# COMPUTE_CLUSTER0_GIC500SS_GICSS_VBUSM_GASKET_CFG_GICSS_VBUSM_GASKET_CFG register map
Vendor: Texas Instruments
Peripheral module from a debugger description file (folder J721S2).
Registers are 32-bit, read-only, reset 0x0 unless marked. A register's access mark holds for its fields unless they carry their own. Offsets are as the file gives them; lines under a group give offsets from that group; [hi:lo] are bit positions; {n}, {i} and the like mark numbered series; 'fields as' and 'values as' point back to an identical list; <NAME> marks a mode.

## COMPUTE_CLUSTER0_GIC500SS_GICSS_VBUSM_GASKET_CFG_GICSS_VBUSM_GASKET_CFG
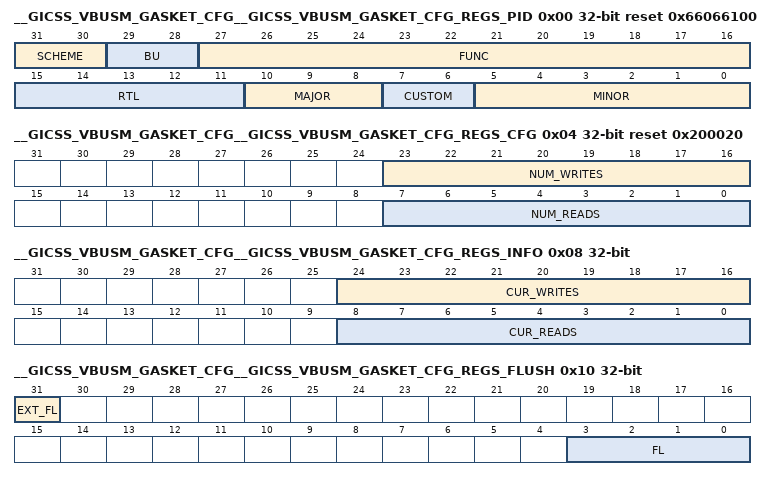
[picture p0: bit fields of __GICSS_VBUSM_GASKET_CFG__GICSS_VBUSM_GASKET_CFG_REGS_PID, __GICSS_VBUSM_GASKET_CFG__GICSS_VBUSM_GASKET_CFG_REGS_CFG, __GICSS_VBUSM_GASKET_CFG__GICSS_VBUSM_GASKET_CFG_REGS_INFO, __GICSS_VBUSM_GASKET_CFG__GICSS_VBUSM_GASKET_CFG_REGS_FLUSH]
0x00 __GICSS_VBUSM_GASKET_CFG__GICSS_VBUSM_GASKET_CFG_REGS_PID reset 0x66066100 — The Revision Register contains the major and minor revisions for the module.
  [31:30] SCHEME — PID register scheme
  [29:28] BU — Business Unit: 10 = Processors
  [27:16] FUNC — Module ID
  [15:11] RTL — RTL revision. Will vary depending on release.
  [10:8] MAJOR — Major revision
  [7:6] CUSTOM
  [5:0] MINOR — Minor revision
0x04 __GICSS_VBUSM_GASKET_CFG__GICSS_VBUSM_GASKET_CFG_REGS_CFG reset 0x200020 — The Configuration Register contains information about the configuration of the gasket.
  [23:16] NUM_WRITES — Total Number of slots in the write scoreboard
  [7:0] NUM_READS — Total Number of slots in the read scoreboard
0x08 __GICSS_VBUSM_GASKET_CFG__GICSS_VBUSM_GASKET_CFG_REGS_INFO — The Info Register contains information about the current state of the gasket.
  [24:16] CUR_WRITES — Total Number of slots in the write scoreboard
  [8:0] CUR_READS — Total Number of slots in the read scoreboard
0x0C __GICSS_VBUSM_GASKET_CFG__GICSS_VBUSM_GASKET_CFG_REGS_ENABLE rw — The Enable Register contains the gasket enable.
  [3:0] EN — Enable. 0 - Disabled, All other values - Enabled.
0x10 __GICSS_VBUSM_GASKET_CFG__GICSS_VBUSM_GASKET_CFG_REGS_FLUSH access per field — The Flush Register contains software flush control.
  [31] EXT_FL ro — External Flush Value
  [3:0] FL rw — Enable. 4'b1111 - Flush, All other values - Normal.
0x14 __GICSS_VBUSM_GASKET_CFG__GICSS_VBUSM_GASKET_CFG_REGS_TIMEOUT rw reset 0x3FFFFFFF — The Timeout Value Register contains the timeout value for scoreboarded transactions.
  [29:0] TO — The number of cycles in each eon.
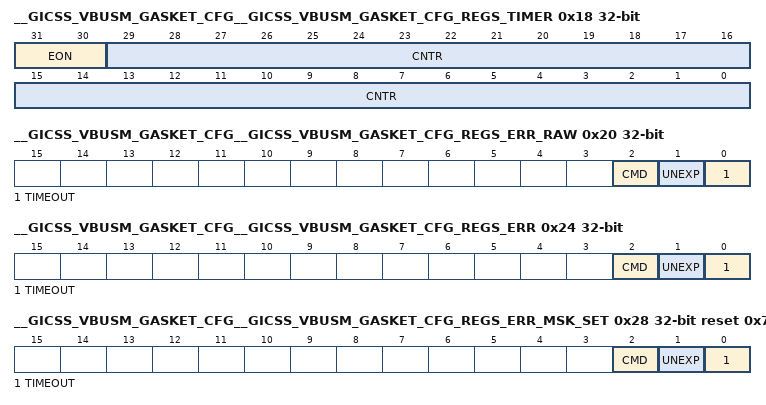
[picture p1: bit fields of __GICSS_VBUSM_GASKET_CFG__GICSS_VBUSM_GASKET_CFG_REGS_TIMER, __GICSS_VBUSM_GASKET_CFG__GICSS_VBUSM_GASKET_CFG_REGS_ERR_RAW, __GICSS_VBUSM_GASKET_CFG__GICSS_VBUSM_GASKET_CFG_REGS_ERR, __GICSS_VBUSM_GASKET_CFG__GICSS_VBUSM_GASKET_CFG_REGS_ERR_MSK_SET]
0x18 __GICSS_VBUSM_GASKET_CFG__GICSS_VBUSM_GASKET_CFG_REGS_TIMER access not given — The Timer Register contains the current value for free-running timer.
  [31:30] EON ro — Current eon
  [29:0] CNTR — Current value of the free-running timer (access R/WTC)
0x20 __GICSS_VBUSM_GASKET_CFG__GICSS_VBUSM_GASKET_CFG_REGS_ERR_RAW access not given — This register contains the masked interrupt bits
  [2] CMD — Raw Command Error Interrupt (access R/W1TS)
  [1] UNEXP — Raw Unexpected Error Interrupt (access R/W1TS)
  [0] TIMEOUT — Raw Timeout Error Interrupt (access R/W1TS)
0x24 __GICSS_VBUSM_GASKET_CFG__GICSS_VBUSM_GASKET_CFG_REGS_ERR access not given — This register contains the masked interrupt bits
  [2] CMD — Masked Command Error Interrupt (access R/W1TC)
  [1] UNEXP — Masked Unexpected Error Interrupt (access R/W1TC)
  [0] TIMEOUT — Masked Timeout Error Interrupt (access R/W1TC)
0x28 __GICSS_VBUSM_GASKET_CFG__GICSS_VBUSM_GASKET_CFG_REGS_ERR_MSK_SET access not given reset 0x7 — This register contains interrupt mask set bits
  [2] CMD — Raw Command Error Interrupt Mask Set (access R/W1TS)
  [1] UNEXP — Raw Unexpected Error Interrupt Mask Set (access R/W1TS)
  [0] TIMEOUT — Raw Timeout Error Interrupt Mask Set (access R/W1TS)
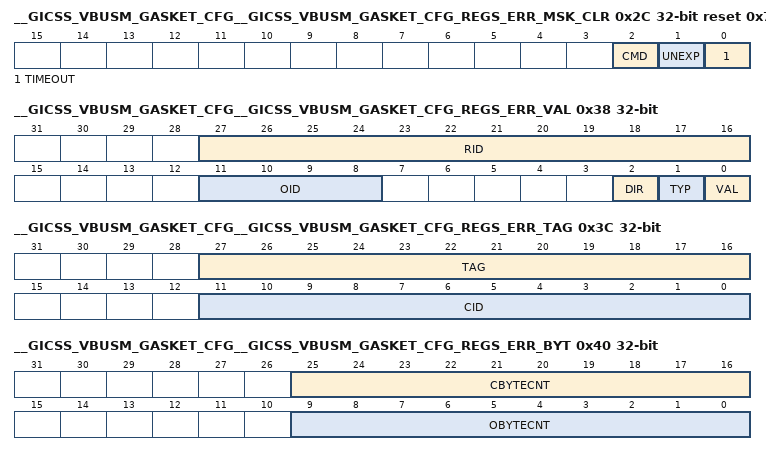
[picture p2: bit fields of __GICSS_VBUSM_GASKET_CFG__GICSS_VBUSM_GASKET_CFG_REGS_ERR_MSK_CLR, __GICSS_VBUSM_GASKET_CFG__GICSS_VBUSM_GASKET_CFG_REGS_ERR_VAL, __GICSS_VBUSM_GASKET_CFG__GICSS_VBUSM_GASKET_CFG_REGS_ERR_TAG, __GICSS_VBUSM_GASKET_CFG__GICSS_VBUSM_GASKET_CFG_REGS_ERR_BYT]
0x2C __GICSS_VBUSM_GASKET_CFG__GICSS_VBUSM_GASKET_CFG_REGS_ERR_MSK_CLR access not given reset 0x7 — This register contains interrupt mask clear bits
  [2] CMD — Raw Command Error Interrupt Mask Clear (access R/W1TC)
  [1] UNEXP — Raw Unexpected Error Interrupt Mask Clear (access R/W1TC)
  [0] TIMEOUT — Raw Timeout Error Interrupt Mask Clear (access R/W1TC)
0x30 __GICSS_VBUSM_GASKET_CFG__GICSS_VBUSM_GASKET_CFG_REGS_ERR_TM_INFO access not given — This register contains information about timeout interrupts
  [1:0] CNT — Timeout Interrupt Count (access R/WTD)
0x34 __GICSS_VBUSM_GASKET_CFG__GICSS_VBUSM_GASKET_CFG_REGS_ERR_UN_INFO access not given — This register contains information about unexpected interrupts
  [1:0] CNT — Unexpected Interrupt Count (access R/WTD)
0x38 __GICSS_VBUSM_GASKET_CFG__GICSS_VBUSM_GASKET_CFG_REGS_ERR_VAL — This register contains information about transaction that caused the interrupt
  [27:16] RID — Route ID Indicator
  [11:8] OID — Order ID Indicator
  [2] DIR — Direction Indicator
  [1] TYP — Type Indicator
  [0] VAL — Valid Indicator
0x3C __GICSS_VBUSM_GASKET_CFG__GICSS_VBUSM_GASKET_CFG_REGS_ERR_TAG — This register contains information about transaction that caused the interrupt
  [27:16] TAG — Command Tag Indicator
  [11:0] CID — Command ID Indicator
0x40 __GICSS_VBUSM_GASKET_CFG__GICSS_VBUSM_GASKET_CFG_REGS_ERR_BYT — This register contains information about transaction that caused the interrupt
  [25:16] CBYTECNT — Current Bytecnt
  [9:0] OBYTECNT — Original Bytecnt
0x44 __GICSS_VBUSM_GASKET_CFG__GICSS_VBUSM_GASKET_CFG_REGS_ERR_ADDR_U — This register contains information about transaction that caused the interrupt
  [31:0] ADDR — Upper bits of the Address
0x48 __GICSS_VBUSM_GASKET_CFG__GICSS_VBUSM_GASKET_CFG_REGS_ERR_ADDR_L — This register contains information about transaction that caused the interrupt
  [31:0] ADDR — Lower bits of the Address
